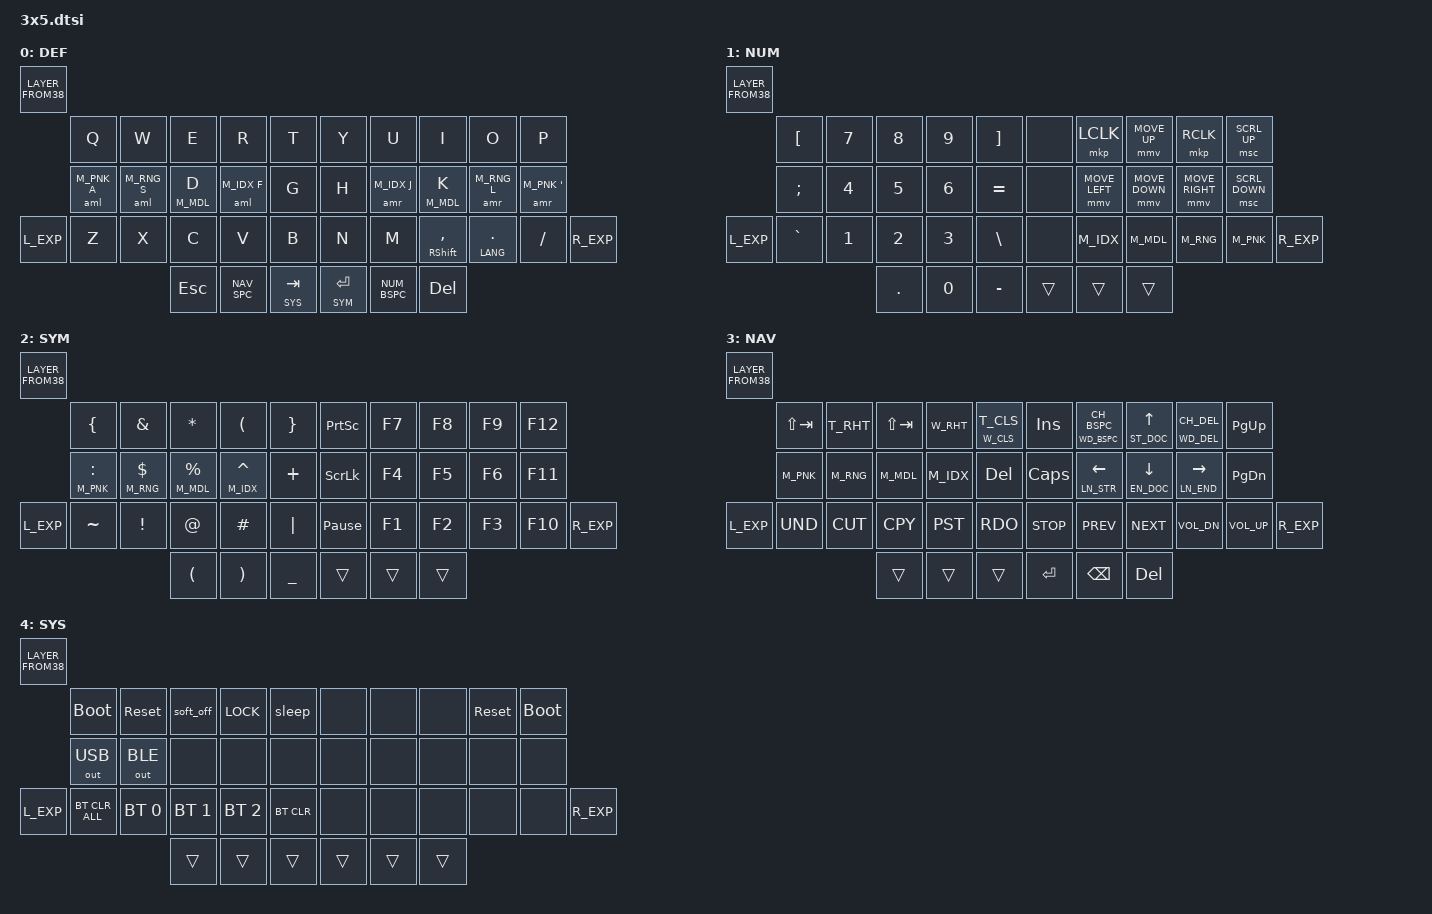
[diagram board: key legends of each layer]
#include <behaviors.dtsi>
#include <dt-bindings/zmk/keys.h>
#include <dt-bindings/zmk/bt.h>
#include <dt-bindings/zmk/outputs.h>
#include <behaviors/rgbled_widget.dtsi> // https://github.com/caksoylar/zmk-rgbled-widget
#include <behaviors/num_word.dtsi> // https://github.com/urob/zmk-auto-layer
#include "zmk-helpers/helper.h" //collection of helper macros. https://github.com/urob/zmk-helpers

// Layer aliases
#define DEF 0
#define NUM 1
#define SYM 2
#define NAV 3
#define SYS 4

#include "shortcut.dtsi"
#include "combos.dtsi"
#include "mouse.dtsi"
#include "behaviors.dtsi"
#include "macros.dtsi"

/ {
    keymap {
        compatible = "zmk,keymap";

        default_layer {
            display-name = "DEF";
            bindings = <LAYER_FROM38( \
//           ╭──────────────┬──────────────┬──────────────┬──────────────┬──────────────╮   ╭──────────────┬──────────────┬──────────────┬──────────────┬──────────────╮
              &kp Q,         &kp W,         &kp E,         &kp R,         &kp T,             &kp Y,         &kp U,         &kp I,         &kp O,         &kp P, \
              &aml M_PNK A,  &aml M_RNG S,  &asl M_MDL D,  &aml M_IDX F,  &kp G,             &kp H,         &amr M_IDX J,  &asr M_MDL K,  &amr M_RNG L,  &amr M_PNK SQT, \
&kp L_EXP,    &kp Z,         &kp X,         &kp C,         &kp V,         &kp B,             &kp N,         &kp M,       &mt RSHFT COMMA, &mt LANG DOT,  &kp SLASH,    &kp R_EXP, \
                                            &kp ESC,       NAV_SPC,       &lt SYS TAB,       &lt SYM RET,   NUM_BSPC,      &kp DEL \
//                                         ╰─────────────┴──────────────┴──────────────╯    ╰──────────────┴──────────────┴──────────────╯
            )>;
        };

        number_layer {
            display-name = "NUM";
            bindings = <LAYER_FROM38( \
//           ╭──────────────┬──────────────┬──────────────┬──────────────┬──────────────╮   ╭──────────────┬──────────────┬──────────────┬──────────────┬──────────────╮
              &kp LBKT,      &kp N7,        &kp N8,        &kp N9,        &kp RBKT,          &none,         &mkp LCLK,     &mmv MOVE_UP,  &mkp RCLK,     &msc SCRL_UP, \
              &kp SEMI,      &kp N4,        &kp N5,        &kp N6,        &kp EQUAL,         &none,         &mmv MOVE_LEFT, &mmv MOVE_DOWN, &mmv MOVE_RIGHT, &msc SCRL_DOWN, \
&kp L_EXP,    &kp GRAVE,     &kp N1,        &kp N2,        &kp N3,        &kp BSLH,          &none,         &kp M_IDX,     &kp M_MDL,     &kp M_RNG,     &kp M_PNK,    &kp R_EXP, \
                                            &kp DOT,       &kp N0,        &kp MINUS,         &trans,        &trans,        &trans \
//                                         ╰──────────────┴──────────────┴──────────────╯   ╰──────────────┴──────────────┴──────────────╯
            )>;
        };

        symbol_layer {
            display-name = "SYM";
            bindings = <LAYER_FROM38( \
//           ╭──────────────┬──────────────┬──────────────┬──────────────┬──────────────╮   ╭──────────────┬──────────────┬──────────────┬──────────────┬──────────────╮
              &kp LBRC,      &kp AMPS,      &kp ASTRK,     &kp LPAR,      &kp RBRC,          &kp PSCRN,     &kp F7,        &kp F8,        &kp F9,        &kp F12, \
              &mt M_PNK COLON, &mt M_RNG DLLR, &mt M_MDL PRCNT, &mt M_IDX CARET, &kp PLUS,   &kp SLCK,      &kp F4,        &kp F5,        &kp F6,        &kp F11, \
&kp L_EXP,    &kp TILDE,     &kp EXCL,      &kp AT,        &kp HASH,      &kp PIPE,          &kp PAUSE_BREAK, &kp F1,      &kp F2,        &kp F3,        &kp F10,      &kp R_EXP, \
                                            &kp LPAR,      &kp RPAR,      &kp UNDER,         &trans,        &trans,        &trans \
//                                         ╰──────────────┴──────────────┴──────────────╯   ╰──────────────┴──────────────┴──────────────╯
            )>;
        };

        navigation_layer {
            display-name = "NAV";
            bindings = <LAYER_FROM38( \
//           ╭──────────────┬──────────────┬──────────────┬──────────────┬──────────────╮   ╭──────────────┬──────────────┬──────────────┬──────────────┬──────────────╮
              &kp LS(TAB),   &T_RHT,        &kp LS(TAB),   &W_RHT,        &ht W_CLS T_CLS,   &kp INS,  &ht WD_BSPC CH_BSPC, &ht ST_DOC UP, &ht WD_DEL CH_DEL, &kp PG_UP, \
              &kp M_PNK,     &kp M_RNG,     &kp M_MDL,     &kp M_IDX,     &kp DEL,           &kp CAPS, &ht LN_STR LEFT,    &ht EN_DOC DOWN, &ht LN_END RIGHT, &kp PG_DN, \
&kp L_EXP,    &kp C_UND,     &kp C_CUT,     &kp C_CPY,     &kp C_PST,     &kp C_RDO,         &kp C_STOP,    &kp C_PREV,    &kp C_NEXT,    &kp C_VOL_DN,  &kp C_VOL_UP, &kp R_EXP, \
                                            &trans,        &trans,        &trans,            &kp RET,       &kp BSPC,      &kp DEL \
//                                         ╰──────────────┴──────────────┴──────────────╯   ╰──────────────┴──────────────┴──────────────╯
            )>;
        };

        system_layer {
            display-name = "SYS";
            bindings = <LAYER_FROM38( \
//           ╭──────────────┬──────────────┬──────────────┬──────────────┬──────────────╮   ╭──────────────┬──────────────┬──────────────┬──────────────┬──────────────╮
              &bootloader,   &sys_reset,    &soft_off,     &kp LOCK,      &sleep,            &none,         &none,         &none,         &sys_reset,    &bootloader, \
              &out OUT_USB,  &out OUT_BLE,  &none,         &none,         &none,             &none,         &none,         &none,         &none,         &none, \
&kp L_EXP,    &bt BT_CLR_ALL, &bt BT_SEL 0, &bt BT_SEL 1,  &bt BT_SEL 2,  &bt BT_CLR,        &none,         &none,         &none,         &none,         &none,         &kp R_EXP, \
                                            &trans,        &trans,        &trans,            &trans,        &trans,        &trans \
//                                         ╰──────────────┴──────────────┴──────────────╯   ╰──────────────┴──────────────┴──────────────╯
            )>;
        };
    };
};
